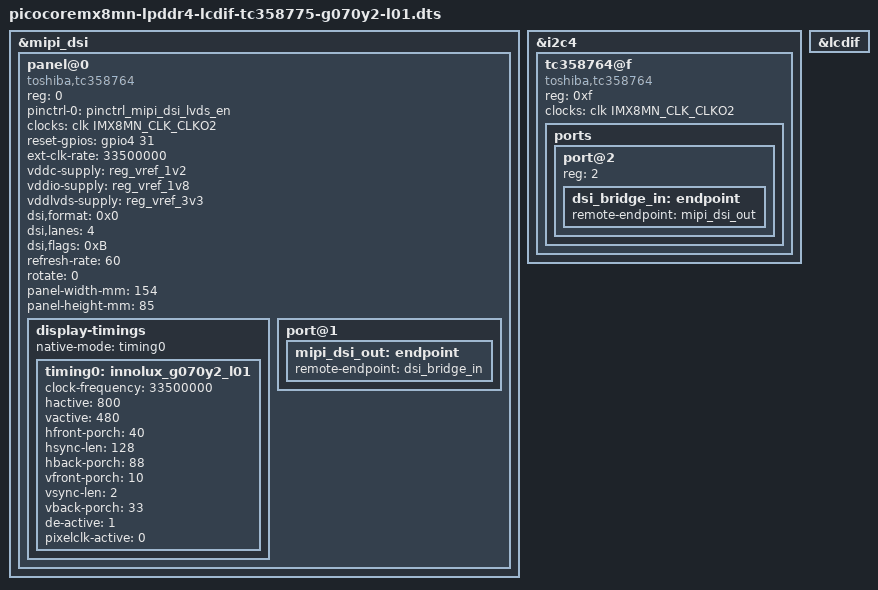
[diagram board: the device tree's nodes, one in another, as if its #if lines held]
/*
* Copyright (C) 2021 F&S Elektronik Systeme GmbH
*
* This program is free software; you can redistribute it and/or modify
* it under the terms of the GNU General Public License version 2 as
* published by the Free Software Foundation.
*/

#define CONFIG_PICOCOREMX8MN_MIPI_DSI_LVDS
#include "picocoremx8mn-lpddr4.dts"

&mipi_dsi {
	status = "okay";

#if 0
/* DSI mode flags */

/* video mode */
#define MIPI_DSI_MODE_VIDEO		BIT(0)
/* video burst mode */
#define MIPI_DSI_MODE_VIDEO_BURST	BIT(1)
/* video pulse mode */
#define MIPI_DSI_MODE_VIDEO_SYNC_PULSE	BIT(2)
/* enable auto vertical count mode */
#define MIPI_DSI_MODE_VIDEO_AUTO_VERT	BIT(3)
/* enable hsync-end packets in vsync-pulse and v-porch area */
#define MIPI_DSI_MODE_VIDEO_HSE		BIT(4)
/* disable hfront-porch area */
#define MIPI_DSI_MODE_VIDEO_HFP		BIT(5)
/* disable hback-porch area */
#define MIPI_DSI_MODE_VIDEO_HBP		BIT(6)
/* disable hsync-active area */
#define MIPI_DSI_MODE_VIDEO_HSA		BIT(7)
/* flush display FIFO on vsync pulse */
#define MIPI_DSI_MODE_VSYNC_FLUSH	BIT(8)
/* disable EoT packets in HS mode */
#define MIPI_DSI_MODE_EOT_PACKET	BIT(9)
/* device supports non-continuous clock behavior (DSI spec 5.6.1) */
#define MIPI_DSI_CLOCK_NON_CONTINUOUS	BIT(10)
/* transmit data in low power */
#define MIPI_DSI_MODE_LPM		BIT(11)
#endif

	panel@0{
		status = "okay";
		compatible = "toshiba,tc358764";
		reg = <0>;
		pinctrl-names = "default";
		pinctrl-0 = <&pinctrl_mipi_dsi_lvds_en>;
		clocks = <&clk IMX8MN_CLK_CLKO2>;
#if CONFIG_PICOCOREMX8MN_BOARD_REVISION >= 130
		reset-gpios = <&gpio4 31 GPIO_ACTIVE_HIGH>;
#else
		reset-gpios = <&gpio1 13 GPIO_ACTIVE_HIGH>;
#endif
		clock-names = "ext-clk";
		ext-clk-rate = <33500000>;
		vddc-supply = <&reg_vref_1v2>;
		vddio-supply = <&reg_vref_1v8>;
		vddlvds-supply = <&reg_vref_3v3>;
		dsi,format = <0x0>; /* MIPI_DSI_FMT_RGB888 */
		dsi,lanes = <4>;
		/* MIPI_DSI_MODE_VIDEO MIPI_DSI_MODE_VIDEO_BURST
		 * MIPI_DSI_MODE_VIDEO_AUTO_VERT
		 */
		dsi,flags = <0xB>;
		refresh-rate = <60>;
		rotate = <0>;
		panel-width-mm = <154>;
		panel-height-mm = <85>;
		display-timings {
			native-mode = <&timing0>;
			timing0: innolux_g070y2_l01 {
				clock-frequency = <33500000>;
				hactive = <800>;
				vactive = <480>;
				hfront-porch = <40>;
				hsync-len = <128>;
				hback-porch = <88>;
				vfront-porch = <10>;
				vsync-len = <2>;
				vback-porch = <33>;
				de-active = <1>;
				pixelclk-active = <0>;
			};
		};
		port@1 {
			mipi_dsi_out: endpoint {
				remote-endpoint = <&dsi_bridge_in>;
			};
		};
	};
};

&i2c4 {
	tc358764@f {
		status = "okay";
		compatible = "toshiba,tc358764";
		reg = <0xf>;
		clocks = <&clk IMX8MN_CLK_CLKO2>;
		clock-names = "ref";
		ports {
			#address-cells = <1>;
			#size-cells = <0>;
			port@2 {
				reg = <2>;
				dsi_bridge_in: endpoint {
					remote-endpoint = <&mipi_dsi_out>;
				};
			};
		};
	};
};

&lcdif {
	status = "okay";
};
